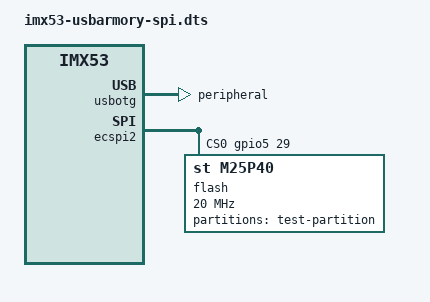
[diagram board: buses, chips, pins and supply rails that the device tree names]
/*
 * USB armory MkI device mode device tree file
 * https://inversepath.com/usbarmory
 *
 * Copyright (C) 2015, Inverse Path
 * Andrej Rosano <andrej@inversepath.com>
 *
 * Licensed under GPLv2
 */

/dts-v1/;

#include "imx53-usbarmory-common.dtsi"

&usbotg {
	dr_mode = "peripheral";
	status = "okay";
};

&uart1 {
	status = "disabled";
};

&iomuxc {
	pinctrl-0 = <&pinctrl_ecspi2>;
};

&ecspi2 {
	fsl,spi-num-chipselects = <2>;
	cs-gpios = <&gpio5 29 0>, <&gpio5 30 0>;
	status = "okay";

	flash: m25p40@0 {
		#address-cells = <1>;
		#size-cells = <1>;
		compatible = "st,m25p40", "st,m25p";
		spi-max-frequency = <20000000>;
		reg = <0>;

		partition@0 {
			label = "test-partition";
			reg = <0x0 0x80000>;
		};
	};
};
